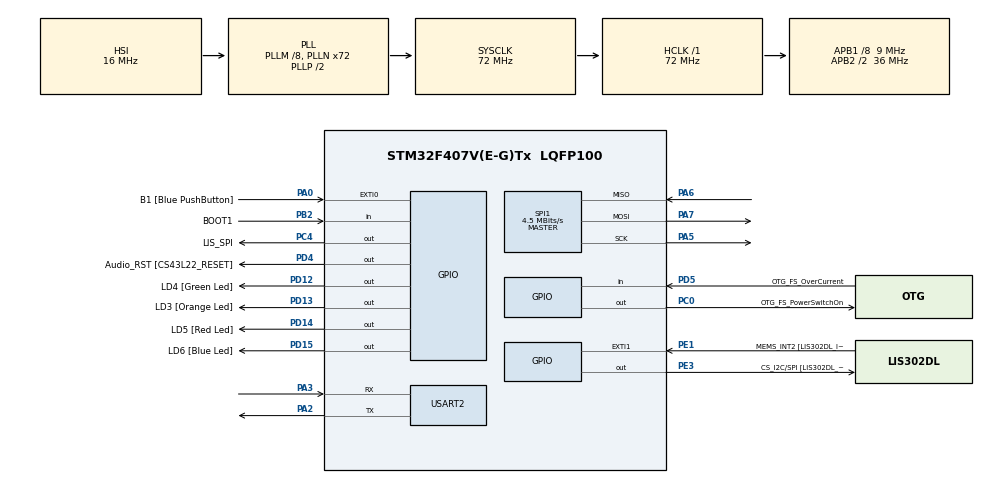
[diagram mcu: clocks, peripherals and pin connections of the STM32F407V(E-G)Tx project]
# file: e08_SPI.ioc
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Mcu.Family=STM32F4
PD12.GPIO_Label=LD4 [Green Led]
PA6.Mode=Full_Duplex_Master
RCC.CortexFreq_Value=72000000
SPI1.VirtualType=VM_MASTER
PD15.GPIO_Speed=GPIO_SPEED_FREQ_LOW
PC0.GPIO_Label=OTG_FS_PowerSwitchOn
RCC.SYSCLKSource=RCC_SYSCLKSOURCE_PLLCLK
ProjectManager.StackSize=0x400
PD13.Signal=GPIO_Output
PD14.GPIO_Speed=GPIO_SPEED_FREQ_LOW
SPI1.CLKPolarity=SPI_POLARITY_HIGH
SPI1.Direction=SPI_DIRECTION_2LINES
RCC.HCLKFreq_Value=72000000
PD4.Signal=GPIO_Output
RCC.APB2TimFreq_Value=72000000
SPI1.CalculateBaudRate=4.5 MBits/s
PE1.Signal=GPXTI1
RCC.AHBFreq_Value=72000000
RCC.HSE_VALUE=8000000
PB2.Signal=GPIO_Input
PC4.GPIO_Speed=GPIO_SPEED_FREQ_HIGH
PC4.GPIO_Label=LIS_SPI
PD5.GPIO_Mode=GPIO_MODE_INPUT
PD14.GPIO_PuPd=GPIO_NOPULL
PB2.GPIO_PuPd=GPIO_NOPULL
PD13.GPIO_Label=LD3 [Orange Led]
Mcu.Package=LQFP100
PA6.Signal=SPI1_MISO
USART2.VirtualMode=VM_ASYNC
PD12.Signal=GPIO_Output
PD5.GPIO_Label=OTG_FS_OverCurrent
PD15.GPIO_PuPd=GPIO_NOPULL
RCC.APB2CLKDivider=RCC_HCLK_DIV2
RCC.APB1TimFreq_Value=18000000
PC0.GPIO_PuPd=GPIO_NOPULL
PC4.GPIO_ModeDefaultOutputPP=GPIO_MODE_OUTPUT_PP
SPI1.BaudRatePrescaler=SPI_BAUDRATEPRESCALER_8
PD15.Signal=GPIO_Output
PC0.PinState=GPIO_PIN_SET
PA3.Signal=USART2_RX
PA5.Mode=Full_Duplex_Master
PD12.GPIO_Speed=GPIO_SPEED_FREQ_LOW
PD15.GPIO_Label=LD6 [Blue Led]
PA7.Mode=Full_Duplex_Master
PC4.PinState=GPIO_PIN_SET
PC4.Signal=GPIO_Output
PE1.GPIO_PuPd=GPIO_NOPULL
PD5.Signal=GPIO_Input
SPI1.CLKPhase=SPI_PHASE_2EDGE
PC0.Signal=GPIO_Output
PE1.GPIO_ModeDefaultEXTI=GPIO_MODE_EVT_RISING
RCC.APB1CLKDivider=RCC_HCLK_DIV8
PA0-WKUP.GPIO_Label=B1 [Blue PushButton]
PA0-WKUP.Signal=GPXTI0
PA3.Mode=Asynchronous
PD4.GPIO_PuPd=GPIO_NOPULL
PC0.GPIO_Speed=GPIO_SPEED_FREQ_LOW
ProjectManager.TargetToolchain=STM32CubeIDE
RCC.LSE_VALUE=32768
PA5.Signal=SPI1_SCK
board=STM32F407G-DISC1
PD13.GPIO_Speed=GPIO_SPEED_FREQ_LOW
RCC.VCOOutputFreq_Value=144000000
PE1.GPIO_Label=MEMS_INT2 [LIS302DL_INT2]
RCC.APB2Freq_Value=36000000
PB2.GPIO_Mode=GPIO_MODE_INPUT
SPI1.Mode=SPI_MODE_MASTER
PD4.GPIO_Label=Audio_RST [CS43L22_RESET]
PD4.GPIO_Speed=GPIO_SPEED_FREQ_LOW
PE3.GPIO_PuPd=GPIO_NOPULL
PD13.GPIO_PuPd=GPIO_NOPULL
PD5.GPIO_PuPd=GPIO_NOPULL
PD14.GPIO_Label=LD5 [Red Led]
Mcu.Name=STM32F407V(E-G)Tx
PA2.Signal=USART2_TX
PD14.Signal=GPIO_Output
RCC.48MHZClocksFreq_Value=20571428.57142857
RCC.SYSCLKFreq_VALUE=72000000
PE3.GPIO_Speed=GPIO_SPEED_FREQ_LOW
PB2.GPIO_Label=BOOT1
ProjectManager.HeapSize=0x200
RCC.HSI_VALUE=16000000
RCC.PLLQ=7
NVIC.PriorityGroup=NVIC_PRIORITYGROUP_0
RCC.PLLM=8
RCC.PLLN=72
PE3.Signal=GPIO_Output
PA2.Mode=Asynchronous
PE3.GPIO_Label=CS_I2C/SPI [LIS302DL_CS_I2C/SPI]
RCC.APB1Freq_Value=9000000
PD12.GPIO_PuPd=GPIO_NOPULL
PA7.Signal=SPI1_MOSI

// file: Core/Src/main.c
/* USER CODE BEGIN Header */
/**
  ******************************************************************************
  * @file           : main.c
  * @brief          : Main program body
  ******************************************************************************
  * @attention
  *
  * <h2><center>&copy; Copyright (c) 2021 STMicroelectronics.
  * All rights reserved.</center></h2>
  *
  * This software component is licensed by ST under BSD 3-Clause license,
  * the "License"; You may not use this file except in compliance with the
  * License. You may obtain a copy of the License at:
  *                        opensource.org/licenses/BSD-3-Clause
  *
  ******************************************************************************
  */
/* USER CODE END Header */
#include "main.h"
#include "spi.h"
#include "usart.h"
#include "gpio.h"

/* USER CODE BEGIN Includes */
#include "lis2dw12_reg.h"
#include "lis2dw12_add.h"
/* USER CODE END Includes */

void SystemClock_Config(void);

int main(void)
{

  /* MCU Configuration--------------------------------------------------------*/

  /* Reset of all peripherals, Initializes the Flash interface and the Systick. */
  HAL_Init();

  /* Configure the system clock */
  SystemClock_Config();

  /* USER CODE BEGIN SysInit */
  // testowy komentarz dla sprawdzenia gita

  /* USER CODE END SysInit */

  /* Initialize all configured peripherals */
  MX_GPIO_Init();
  MX_SPI1_Init();
  MX_USART2_UART_Init();
  /* USER CODE BEGIN 2 */
  lis2dw12_init();
  /* USER CODE END 2 */

  /* Infinite loop */
  /* USER CODE BEGIN WHILE */
  while (1)
  {
	  lis2dw12_read_data();
    /* USER CODE END WHILE */

  }
}

void SystemClock_Config(void)
{
  RCC_OscInitTypeDef RCC_OscInitStruct = {0};
  RCC_ClkInitTypeDef RCC_ClkInitStruct = {0};

  /** Configure the main internal regulator output voltage
  */
  __HAL_RCC_PWR_CLK_ENABLE();
  __HAL_PWR_VOLTAGESCALING_CONFIG(PWR_REGULATOR_VOLTAGE_SCALE1);
  /** Initializes the RCC Oscillators according to the specified parameters
  * in the RCC_OscInitTypeDef structure.
  */
  RCC_OscInitStruct.OscillatorType = RCC_OSCILLATORTYPE_HSI;
  RCC_OscInitStruct.HSIState = RCC_HSI_ON;
  RCC_OscInitStruct.HSICalibrationValue = RCC_HSICALIBRATION_DEFAULT;
  RCC_OscInitStruct.PLL.PLLState = RCC_PLL_ON;
  RCC_OscInitStruct.PLL.PLLSource = RCC_PLLSOURCE_HSI;
  RCC_OscInitStruct.PLL.PLLM = 8;
  RCC_OscInitStruct.PLL.PLLN = 72;
  RCC_OscInitStruct.PLL.PLLP = RCC_PLLP_DIV2;
  RCC_OscInitStruct.PLL.PLLQ = 7;
  if (HAL_RCC_OscConfig(&RCC_OscInitStruct) != HAL_OK)
  {
    Error_Handler();
  }
  /** Initializes the CPU, AHB and APB buses clocks
  */
  RCC_ClkInitStruct.ClockType = RCC_CLOCKTYPE_HCLK|RCC_CLOCKTYPE_SYSCLK
                              |RCC_CLOCKTYPE_PCLK1|RCC_CLOCKTYPE_PCLK2;
  RCC_ClkInitStruct.SYSCLKSource = RCC_SYSCLKSOURCE_PLLCLK;
  RCC_ClkInitStruct.AHBCLKDivider = RCC_SYSCLK_DIV1;
  RCC_ClkInitStruct.APB1CLKDivider = RCC_HCLK_DIV8;
  RCC_ClkInitStruct.APB2CLKDivider = RCC_HCLK_DIV2;

  if (HAL_RCC_ClockConfig(&RCC_ClkInitStruct, FLASH_LATENCY_2) != HAL_OK)
  {
    Error_Handler();
  }
}

void Error_Handler(void)
{
  __disable_irq();
  while (1)
  {
  }
}

/************************ (C) COPYRIGHT STMicroelectronics *****END OF FILE****/
